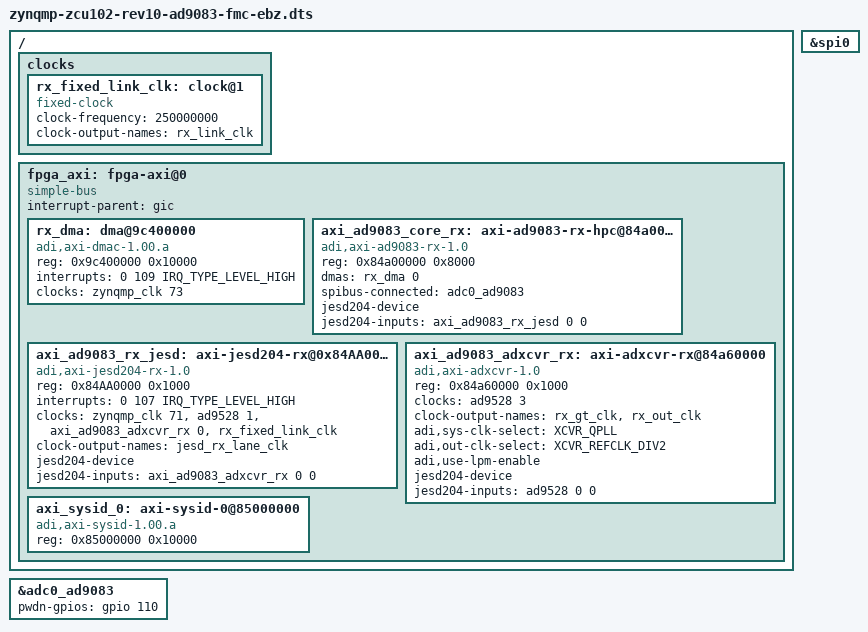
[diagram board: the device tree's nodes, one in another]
// SPDX-License-Identifier: GPL-2.0
/*
 * Analog Devices AD9083-FMC-EBZ
 * https://wiki.analog.com/resources/eval/dpg/ad9083-fmc-ebz
 * https://wiki.analog.com/resources/eval/dpg/eval-ad9083
 *
 * hdl_project: <adc_fmc_ebz/zcu102>
 * board_revision: <>
 *
 * Copyright (C) 2021 Analog Devices Inc.
 */

#include "zynqmp-zcu102-rev1.0.dts"
#include <dt-bindings/interrupt-controller/irq.h>
#include <dt-bindings/jesd204/adxcvr.h>

/ {
	clocks {
		rx_fixed_link_clk: clock@1 {
			#clock-cells = <0>;
			compatible = "fixed-clock";
			clock-frequency = <250000000>;
			clock-output-names = "rx_link_clk";
		};
	};

	fpga_axi: fpga-axi@0 {
		interrupt-parent = <&gic>;
		compatible = "simple-bus";
		#address-cells = <0x1>;
		#size-cells = <0x1>;
		ranges = <0 0 0 0xffffffff>;

		rx_dma: dma@9c400000 {
			compatible = "adi,axi-dmac-1.00.a";
			reg = <0x9c400000 0x10000>;
			#dma-cells = <1>;
			#clock-cells = <0>;
			interrupts = <0 109 IRQ_TYPE_LEVEL_HIGH>;
			clocks = <&zynqmp_clk 73>;
		};

		axi_ad9083_core_rx: axi-ad9083-rx-hpc@84a00000 {
			compatible = "adi,axi-ad9083-rx-1.0";
			reg = <0x84a00000 0x8000>;
			dmas = <&rx_dma 0>;
			dma-names = "rx";
			spibus-connected = <&adc0_ad9083>;

			jesd204-device;
			#jesd204-cells = <2>;
			jesd204-inputs = <&axi_ad9083_rx_jesd 0 0>;
		};

		axi_ad9083_rx_jesd: axi-jesd204-rx@0x84AA0000 {
			compatible = "adi,axi-jesd204-rx-1.0";
			reg = <0x84AA0000 0x1000>;

			interrupts = <0 107 IRQ_TYPE_LEVEL_HIGH>;

			clocks = <&zynqmp_clk 71>, <&ad9528 1>, <&axi_ad9083_adxcvr_rx 0>, <&rx_fixed_link_clk>;
			clock-names = "s_axi_aclk", "device_clk", "lane_clk", "link_clk";

			#clock-cells = <0>;
			clock-output-names = "jesd_rx_lane_clk";

			jesd204-device;
			#jesd204-cells = <2>;
			jesd204-inputs = <&axi_ad9083_adxcvr_rx 0 0>;
		};

		axi_ad9083_adxcvr_rx: axi-adxcvr-rx@84a60000 {
			#address-cells = <1>;
			#size-cells = <0>;
			compatible = "adi,axi-adxcvr-1.0";
			reg = <0x84a60000 0x1000>;

			clocks = <&ad9528 3>;
			clock-names = "conv";

			#clock-cells = <1>;
			clock-output-names = "rx_gt_clk", "rx_out_clk";

			adi,sys-clk-select = <XCVR_QPLL>;
			adi,out-clk-select = <XCVR_REFCLK_DIV2>;
			adi,use-lpm-enable;

			jesd204-device;
			#jesd204-cells = <2>;
			jesd204-inputs = <&ad9528 0 0>;
		};

		axi_sysid_0: axi-sysid-0@85000000 {
			compatible = "adi,axi-sysid-1.00.a";
			reg = <0x85000000 0x10000>;
		};

	};
};

&spi0 {
	status = "okay";
};

#include "adi-ad9083-fmc-ebz.dtsi"

&adc0_ad9083 {
	/* software reset, resistor is not mounted */
	/* reset-gpios = <&gpio 111 0>; */
	pwdn-gpios = <&gpio 110 0>;
};
